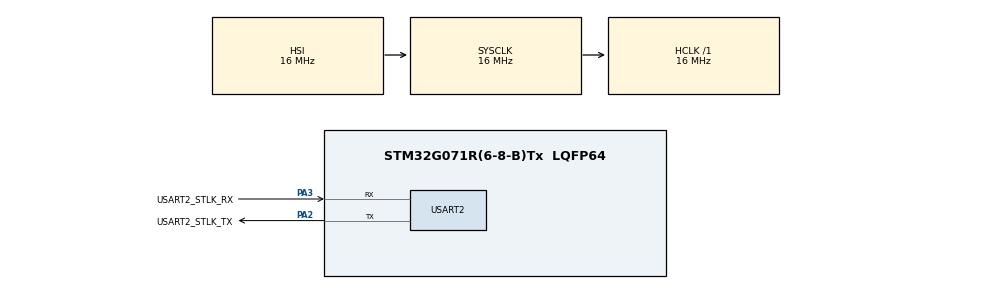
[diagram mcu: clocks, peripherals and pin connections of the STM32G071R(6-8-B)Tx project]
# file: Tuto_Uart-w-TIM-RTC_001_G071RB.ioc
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Dma.Request0=USART2_RX
Dma.USART2_RX.0.Direction=DMA_PERIPH_TO_MEMORY
Dma.USART2_RX.0.EventEnable=DISABLE
Dma.USART2_RX.0.Instance=DMA1_Channel1
Dma.USART2_RX.0.MemDataAlignment=DMA_MDATAALIGN_BYTE
Dma.USART2_RX.0.MemInc=DMA_MINC_ENABLE
Dma.USART2_RX.0.Mode=DMA_NORMAL
Dma.USART2_RX.0.PeriphDataAlignment=DMA_PDATAALIGN_BYTE
Dma.USART2_RX.0.PeriphInc=DMA_PINC_DISABLE
Dma.USART2_RX.0.Polarity=HAL_DMAMUX_REQ_GEN_RISING
Dma.USART2_RX.0.Priority=DMA_PRIORITY_LOW
Dma.USART2_RX.0.RequestNumber=1
Dma.USART2_RX.0.SignalID=NONE
Dma.USART2_RX.0.SyncEnable=DISABLE
Dma.USART2_RX.0.SyncPolarity=HAL_DMAMUX_SYNC_NO_EVENT
Dma.USART2_RX.0.SyncRequestNumber=1
Dma.USART2_RX.0.SyncSignalID=NONE
Mcu.Family=STM32G0
Mcu.Name=STM32G071R(6-8-B)Tx
Mcu.Package=LQFP64
NVIC.DMA1_Channel1_IRQn=true\:0\:0\:false\:false\:true\:false\:true\:true
NVIC.RTC_TAMP_IRQn=true\:0\:0\:false\:false\:true\:true\:true\:true
NVIC.TIM14_IRQn=true\:0\:0\:false\:false\:true\:true\:true\:true
NVIC.USART2_IRQn=true\:0\:0\:false\:false\:true\:true\:true\:true
PA13.GPIO_Label=TMS
PA13.Mode=Serial_Wire
PA13.Signal=SYS_SWDIO
PA14-BOOT0.GPIO_Label=TCK
PA14-BOOT0.Mode=Serial_Wire
PA14-BOOT0.Signal=SYS_SWCLK
PA2.GPIO_Label=USART2_STLK_TX
PA2.GPIO_PuPd=GPIO_PULLUP
PA2.Mode=Asynchronous
PA2.Signal=USART2_TX
PA3.GPIO_Label=USART2_STLK_RX
PA3.GPIO_PuPd=GPIO_PULLUP
PA3.Mode=Asynchronous
PA3.Signal=USART2_RX
PC14-OSC32_IN\ (PC14).Mode=LSE-External-Oscillator
PC14-OSC32_IN\ (PC14).Signal=RCC_OSC32_IN
PC15-OSC32_OUT\ (PC15).Mode=LSE-External-Oscillator
PC15-OSC32_OUT\ (PC15).Signal=RCC_OSC32_OUT
PF0-OSC_IN\ (PF0).GPIO_Label=MCO
PF0-OSC_IN\ (PF0).Mode=HSE-External-Clock-Source
PF0-OSC_IN\ (PF0).Signal=RCC_OSC_IN
ProjectManager.HeapSize=0x200
ProjectManager.StackSize=0x400
ProjectManager.TargetToolchain=STM32CubeIDE
RCC.AHBFreq_Value=16000000
RCC.CortexFreq_Value=16000000
RCC.EXTERNAL_CLOCK_VALUE=12288000
RCC.HCLKFreq_Value=16000000
RCC.HSE_VALUE=8000000
RCC.HSI_VALUE=16000000
RCC.RTCClockSelection=RCC_RTCCLKSOURCE_LSE
RCC.SYSCLKFreq_VALUE=16000000
RCC.VCOOutputFreq_Value=128000000
RTC.WakeUpClock-WakeUp=RTC_WAKEUPCLOCK_CK_SPRE_16BITS
RTC.WakeUpCounter-WakeUp=10
TIM14.Period=5000-1
TIM14.Prescaler=16000-1
USART2.VirtualMode-Asynchronous=VM_ASYNC
VP_RTC_VS_RTC_Activate.Mode=RTC_Enabled
VP_RTC_VS_RTC_WakeUp_intern.Mode=WakeUp
VP_TIM14_VS_ClockSourceINT.Mode=Enable_Timer
board=NUCLEO-G071RB

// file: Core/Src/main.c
/* USER CODE BEGIN Header */
/**
  ******************************************************************************
  * @file           : main.c
  * @brief          : Main program body
  ******************************************************************************
  * @attention
  *
  * Copyright (c) 2022 STMicroelectronics.
  * All rights reserved.
  *
  * This software is licensed under terms that can be found in the LICENSE file
  * in the root directory of this software component.
  * If no LICENSE file comes with this software, it is provided AS-IS.
  *
  ******************************************************************************
  */
/* USER CODE END Header */
#include "main.h"

/* USER CODE BEGIN Includes */
#include <stdio.h>
#include <string.h>
/* USER CODE END Includes */

/* USER CODE BEGIN PD */
#define UART_HANDLER				&huart2
#define UART_TX_TIMEOUT				100
#define UART_RX_MAX_BUFF_SIZE		100
#define UART_TX_MAX_BUFF_SIZE		250
/* USER CODE END PD */

RTC_HandleTypeDef hrtc;

TIM_HandleTypeDef htim14;

UART_HandleTypeDef huart2;
DMA_HandleTypeDef hdma_usart2_rx;

/* USER CODE BEGIN PV */
char             	uart_rx_buff[UART_RX_MAX_BUFF_SIZE] ;
char             	uart_tx_buff[UART_TX_MAX_BUFF_SIZE] ;
const char*        	request = "request" ;
const char* 		expected_answer = "answer" ;
uint8_t				answer_come = 0 ;
uint8_t				tim14_on ;
uint8_t				i = 0 ;
/* USER CODE END PV */

void SystemClock_Config(void);
static void MX_GPIO_Init(void);
static void MX_DMA_Init(void);
static void MX_USART2_UART_Init(void);
static void MX_RTC_Init(void);
static void MX_TIM14_Init(void);
/* USER CODE BEGIN PFP */
uint8_t				uart_comm 			( const char* , const char* , uint16_t ) ;
void				receive_dma_uart	( void ) ;
HAL_StatusTypeDef 	send_string_2_uart	( char* ) ;
/* USER CODE END PFP */

int main(void)
{

  /* MCU Configuration--------------------------------------------------------*/

  /* Reset of all peripherals, Initializes the Flash interface and the Systick. */
  HAL_Init();

  /* Configure the system clock */
  SystemClock_Config();

  /* Initialize all configured peripherals */
  MX_GPIO_Init();
  MX_DMA_Init();
  MX_USART2_UART_Init();
  MX_RTC_Init();
  MX_TIM14_Init();
  /* USER CODE BEGIN 2 */
  __HAL_TIM_CLEAR_IT ( &htim14 , TIM_IT_UPDATE ) ; // żeby nie generować przerwania TIM6 od razu: https://stackoverflow.com/questions/71099885/why-hal-tim-periodelapsedcallback-gets-called-immediately-after-hal-tim-base-sta
  /* USER CODE END 2 */

  /* Infinite loop */
  /* USER CODE BEGIN WHILE */
  while ( 1 )
  {
	  uart_comm ( request , expected_answer , i ) ;
	  i++ ;
	  HAL_PWR_EnterSTOPMode ( PWR_LOWPOWERREGULATOR_ON , PWR_STOPENTRY_WFI ) ;
    /* USER CODE END WHILE */

  }
}

void SystemClock_Config(void)
{
  RCC_OscInitTypeDef RCC_OscInitStruct = {0};
  RCC_ClkInitTypeDef RCC_ClkInitStruct = {0};

  /** Configure the main internal regulator output voltage
  */
  HAL_PWREx_ControlVoltageScaling(PWR_REGULATOR_VOLTAGE_SCALE1);

  /** Configure LSE Drive Capability
  */
  HAL_PWR_EnableBkUpAccess();
  __HAL_RCC_LSEDRIVE_CONFIG(RCC_LSEDRIVE_LOW);

  /** Initializes the RCC Oscillators according to the specified parameters
  * in the RCC_OscInitTypeDef structure.
  */
  RCC_OscInitStruct.OscillatorType = RCC_OSCILLATORTYPE_HSI|RCC_OSCILLATORTYPE_LSE;
  RCC_OscInitStruct.LSEState = RCC_LSE_ON;
  RCC_OscInitStruct.HSIState = RCC_HSI_ON;
  RCC_OscInitStruct.HSIDiv = RCC_HSI_DIV1;
  RCC_OscInitStruct.HSICalibrationValue = RCC_HSICALIBRATION_DEFAULT;
  RCC_OscInitStruct.PLL.PLLState = RCC_PLL_NONE;
  if (HAL_RCC_OscConfig(&RCC_OscInitStruct) != HAL_OK)
  {
    Error_Handler();
  }

  /** Initializes the CPU, AHB and APB buses clocks
  */
  RCC_ClkInitStruct.ClockType = RCC_CLOCKTYPE_HCLK|RCC_CLOCKTYPE_SYSCLK
                              |RCC_CLOCKTYPE_PCLK1;
  RCC_ClkInitStruct.SYSCLKSource = RCC_SYSCLKSOURCE_HSI;
  RCC_ClkInitStruct.AHBCLKDivider = RCC_SYSCLK_DIV1;
  RCC_ClkInitStruct.APB1CLKDivider = RCC_HCLK_DIV1;

  if (HAL_RCC_ClockConfig(&RCC_ClkInitStruct, FLASH_LATENCY_0) != HAL_OK)
  {
    Error_Handler();
  }
}

static void MX_RTC_Init(void)
{

  /** Initialize RTC Only
  */
  hrtc.Instance = RTC;
  hrtc.Init.HourFormat = RTC_HOURFORMAT_24;
  hrtc.Init.AsynchPrediv = 127;
  hrtc.Init.SynchPrediv = 255;
  hrtc.Init.OutPut = RTC_OUTPUT_DISABLE;
  hrtc.Init.OutPutRemap = RTC_OUTPUT_REMAP_NONE;
  hrtc.Init.OutPutPolarity = RTC_OUTPUT_POLARITY_HIGH;
  hrtc.Init.OutPutType = RTC_OUTPUT_TYPE_OPENDRAIN;
  hrtc.Init.OutPutPullUp = RTC_OUTPUT_PULLUP_NONE;
  if (HAL_RTC_Init(&hrtc) != HAL_OK)
  {
    Error_Handler();
  }

  /** Enable the WakeUp
  */
  if (HAL_RTCEx_SetWakeUpTimer_IT(&hrtc, 10, RTC_WAKEUPCLOCK_CK_SPRE_16BITS) != HAL_OK)
  {
    Error_Handler();
  }

}

static void MX_TIM14_Init(void)
{

  htim14.Instance = TIM14;
  htim14.Init.Prescaler = 16000-1;
  htim14.Init.CounterMode = TIM_COUNTERMODE_UP;
  htim14.Init.Period = 5000-1;
  htim14.Init.ClockDivision = TIM_CLOCKDIVISION_DIV1;
  htim14.Init.AutoReloadPreload = TIM_AUTORELOAD_PRELOAD_DISABLE;
  if (HAL_TIM_Base_Init(&htim14) != HAL_OK)
  {
    Error_Handler();
  }

}

static void MX_USART2_UART_Init(void)
{

  huart2.Instance = USART2;
  huart2.Init.BaudRate = 115200;
  huart2.Init.WordLength = UART_WORDLENGTH_8B;
  huart2.Init.StopBits = UART_STOPBITS_1;
  huart2.Init.Parity = UART_PARITY_NONE;
  huart2.Init.Mode = UART_MODE_TX_RX;
  huart2.Init.HwFlowCtl = UART_HWCONTROL_NONE;
  huart2.Init.OverSampling = UART_OVERSAMPLING_16;
  huart2.Init.OneBitSampling = UART_ONE_BIT_SAMPLE_DISABLE;
  huart2.Init.ClockPrescaler = UART_PRESCALER_DIV1;
  huart2.AdvancedInit.AdvFeatureInit = UART_ADVFEATURE_NO_INIT;
  if (HAL_UART_Init(&huart2) != HAL_OK)
  {
    Error_Handler();
  }
  if (HAL_UARTEx_SetTxFifoThreshold(&huart2, UART_TXFIFO_THRESHOLD_1_8) != HAL_OK)
  {
    Error_Handler();
  }
  if (HAL_UARTEx_SetRxFifoThreshold(&huart2, UART_RXFIFO_THRESHOLD_1_8) != HAL_OK)
  {
    Error_Handler();
  }
  if (HAL_UARTEx_DisableFifoMode(&huart2) != HAL_OK)
  {
    Error_Handler();
  }

}

static void MX_DMA_Init(void)
{

  /* DMA controller clock enable */
  __HAL_RCC_DMA1_CLK_ENABLE();

  /* DMA interrupt init */
  /* DMA1_Channel1_IRQn interrupt configuration */
  HAL_NVIC_SetPriority(DMA1_Channel1_IRQn, 0, 0);
  HAL_NVIC_EnableIRQ(DMA1_Channel1_IRQn);

}

static void MX_GPIO_Init(void)
{

  /* GPIO Ports Clock Enable */
  __HAL_RCC_GPIOC_CLK_ENABLE();
  __HAL_RCC_GPIOF_CLK_ENABLE();
  __HAL_RCC_GPIOA_CLK_ENABLE();

}

/* USER CODE BEGIN 4 */
uint8_t uart_comm ( const char* r , const char* a , uint16_t n )
{
	uint8_t t ;
	uint8_t expected_answer_come = 0 ;
	sprintf ( uart_tx_buff , "%s%d" , r , n ) ;

	receive_dma_uart () ;
	for ( t = 0 ; t < 5 ; t++ )
	{
		tim14_on = 1 ;
		HAL_TIM_Base_Start_IT ( &htim14 ) ;
		answer_come = 0 ;

		send_string_2_uart ( uart_tx_buff ) ;
		while ( tim14_on )
		{
			if ( answer_come == 1 )
			{
				if ( strncmp ( uart_rx_buff , a , strlen ( a ) ) == 0 )
				{
					expected_answer_come = 1 ;
					// I want to show how many tries was done to get expected answer
					// I can use uart_tx_buff because function is closing.
					sprintf ( uart_tx_buff , "%s.%d" , uart_rx_buff , t ) ;
					send_string_2_uart ( uart_tx_buff ) ;
				}
				receive_dma_uart () ;
				break ;
			}
		}
		if ( expected_answer_come == 1 )
			break ;
	}
	return expected_answer_come ;
}

HAL_StatusTypeDef send_string_2_uart ( char* s )
{
	return HAL_UART_Transmit ( UART_HANDLER , (uint8_t *) s , strlen ( s ) , UART_TX_TIMEOUT ) ;
}

void receive_dma_uart ()
{
	HAL_UARTEx_ReceiveToIdle_DMA ( UART_HANDLER , (uint8_t*) uart_rx_buff , UART_RX_MAX_BUFF_SIZE ) ;
	__HAL_DMA_DISABLE_IT ( &hdma_usart2_rx, DMA_IT_HT ) ; //Disable Half Transfer interrupt.
}

void HAL_UARTEx_RxEventCallback ( UART_HandleTypeDef *huart , uint16_t Size )
{
    if ( huart->Instance == USART2 )
    {
		uart_rx_buff[Size] = '\0' ;
		answer_come = 1 ;
    }
}

void HAL_TIM_PeriodElapsedCallback ( TIM_HandleTypeDef *htim )
{
	if ( htim->Instance == TIM14 )
	{
		tim14_on = 0 ;
		HAL_TIM_Base_Stop_IT ( &htim14 ) ;
	}
}
/* USER CODE END 4 */

void Error_Handler(void)
{
  __disable_irq();
  while (1)
  {
  }
}
